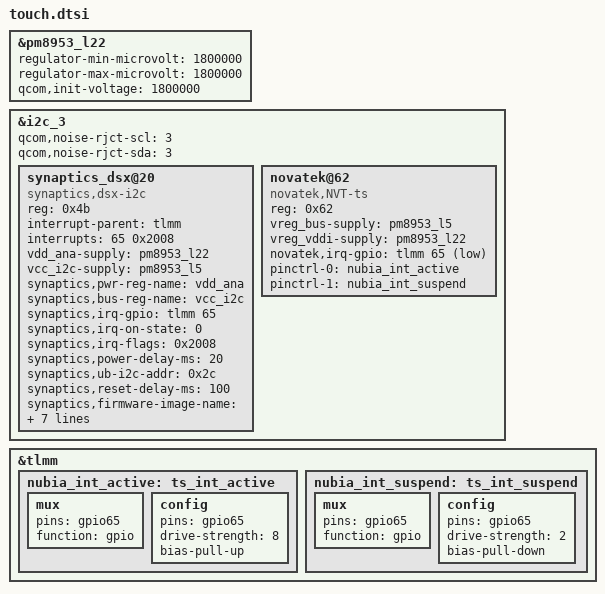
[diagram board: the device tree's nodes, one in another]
/*
 * Copyright (c) 2015-2016, The Linux Foundation. All rights reserved.
 *
 * This program is free software; you can redistribute it and/or modify
 * it under the terms of the GNU General Public License version 2 and
 * only version 2 as published by the Free Software Foundation.
 *
 * This program is distributed in the hope that it will be useful,
 * but WITHOUT ANY WARRANTY; without even the implied warranty of
 * MERCHANTABILITY or FITNESS FOR A PARTICULAR PURPOSE.  See the
 * GNU General Public License for more details.
 */


/*
 * ADD synaptics touch
 */

&pm8953_l22 {
	regulator-min-microvolt = <1800000>;
	regulator-max-microvolt = <1800000>;
	qcom,init-voltage = <1800000>;
};

&i2c_3 {
	status = "okay";

	qcom,noise-rjct-scl = <3>;
	qcom,noise-rjct-sda = <3>;
	synaptics_dsx@20 {
		status = "okay";
		compatible = "synaptics,dsx-i2c";
		reg = <0x4b>;
		interrupt-parent = <&tlmm>;
		interrupts = <65 0x2008>;
		vdd_ana-supply = <&pm8953_l22>;
		vcc_i2c-supply = <&pm8953_l5>;
		synaptics,pwr-reg-name = "vdd_ana";
		synaptics,bus-reg-name = "vcc_i2c";
		synaptics,irq-gpio = <&tlmm 65 0x2008>;
		synaptics,irq-on-state = <0>;
		synaptics,irq-flags = <0x2008>;  //IRQF_ONESHOT | IRQF_TRIGGER_LOW
		synaptics,power-delay-ms = <20>;
		synaptics,ub-i2c-addr = <0x2c>;
		synaptics,reset-delay-ms = <100>;
		synaptics,firmware-image-name = "nubia_tp_jdi_fw.img";
		pinctrl-names = "synaptics_pin_active", "synaptics_pin_suspend";
		pinctrl-0 = <&nubia_int_active>;
		pinctrl-1 = <&nubia_int_suspend>;
		synaptics,full_raw_limit_upper = <
			3191 3164 3092 3075 3136 3067 3068 3095 3017 3011 3035 2990 2994 3042 2991 2958 3033 2950 2967 3025 2970 2975 3021 2981 2984 3035 3004 3010 3079 2984 3048 3158
			2880 2904 2849 2851 2915 2851 2866 2912 2861 2876 2951 2867 2892 2936 2898 2877 2961 2888 2898 2965 2904 2917 2955 2918 2924 2980 2944 2956 3018 2926 2987 3106
			2882 2904 2855 2864 2930 2861 2880 2922 2874 2887 2937 2882 2894 2948 2913 2894 2978 2905 2917 2985 2925 2938 2980 2939 2947 3005 2969 2980 3040 2944 3006 3126
			2893 2910 2861 2871 2939 2871 2892 2938 2883 2903 2956 2893 2909 2978 2925 2909 3004 2919 2935 3009 2941 2959 3015 2956 2974 3035 2988 3004 3079 2956 3049 3158
			2910 2932 2861 2885 2951 2875 2909 2944 2892 2923 2960 2902 2926 2983 2935 2926 3016 2931 2957 3015 2955 2982 3026 2971 2995 3047 3003 3021 3088 2968 3059 3165
			2908 2918 2857 2882 2943 2876 2910 2951 2895 2924 2969 2906 2930 2988 2939 2931 3020 2935 2964 3022 2962 2991 3036 2979 3003 3055 3007 3025 3090 2971 3061 3163
			2899 2911 2852 2878 2941 2875 2910 2951 2895 2926 2970 2908 2933 2990 2941 2935 3023 2938 2966 3025 2964 2995 3039 2983 3009 3060 3011 3031 3095 2973 3066 3163
			2894 2905 2847 2876 2939 2874 2910 2951 2893 2927 2970 2907 2933 2989 2940 2934 3023 2938 2967 3030 2964 2995 3045 2983 3007 3067 3009 3034 3122 2970 3042 3110
			2874 2846 2843 2846 2935 2872 2896 2953 2893 2915 2968 2907 2918 2989 2940 2923 3022 2939 2957 3034 2966 2987 3041 2984 2996 3057 3009 3010 3079 2970 3026 3150
			2880 2868 2922 2853 2876 2946 2890 2897 2979 2889 2911 2993 2936 2932 3007 2953 2974 3023 2958 2973 3063 2978 3014 3069 3007 3022 3083 3002 3009 3033 3016 3057
			2863 2900 2971 2853 2911 2964 2890 2906 2986 2889 2923 2990 2933 2943 3005 2952 2987 3026 2957 2987 3055 2979 3030 3069 3008 3039 3091 3005 3041 3090 3019 3085
			2865 2913 2951 2856 2908 2954 2891 2906 2979 2890 2923 2982 2934 2942 3005 2951 2985 3025 2956 2986 3056 2978 3030 3071 3011 3041 3094 3007 3041 3090 3018 3078
			2872 2917 2956 2859 2909 2955 2893 2905 2978 2889 2921 2979 2932 2940 3002 2948 2981 3023 2954 2982 3053 2977 3027 3068 3008 3039 3092 3006 3040 3090 3018 3073
			2873 2919 2958 2861 2907 2955 2893 2904 2977 2887 2918 2977 2929 2935 2999 2946 2977 3019 2950 2977 3047 2971 3023 3057 3003 3036 3087 3004 3037 3093 3013 3073
			2874 2913 2964 2860 2900 2957 2889 2894 2975 2880 2902 2976 2922 2918 2993 2938 2959 3008 2939 2958 3044 2960 2999 3049 2993 3014 3071 2995 3017 3069 3005 3054
			2872 2893 2941 2856 2887 2936 2883 2878 2955 2871 2890 2957 2913 2906 2971 2927 2943 2980 2926 2941 3018 2945 2980 3025 2977 2996 3051 2982 3003 3056 2993 3041
			2875 2893 2937 2850 2877 2926 2874 2869 2944 2859 2878 2945 2900 2893 2957 2914 2928 2964 2909 2939 3032 2927 2962 3004 2954 2973 3034 2963 2982 3034 2977 3022
			2956 2960 3002 2910 2938 2979 2938 2931 3005 2923 2931 3012 2968 2959 3022 2980 2998 3048 3003 3028 3106 3042 3068 3135 3112 3150 3227 3173 3196 3255 3223 3308

		>;
		synaptics,full_raw_limit_lower = <
			1718 1704 1665 1656 1689 1651 1652 1667 1625 1621 1634 1610 1612 1638 1611 1593 1633 1589 1598 1629 1599 1602 1627 1605 1607 1634 1617 1621 1658 1607 1641 1701
			1551 1564 1534 1535 1570 1535 1543 1568 1541 1549 1589 1544 1557 1581 1560 1549 1595 1555 1560 1596 1564 1571 1591 1571 1574 1604 1585 1592 1625 1576 1608 1673
			1552 1564 1538 1542 1577 1541 1551 1574 1547 1555 1582 1552 1558 1588 1569 1558 1604 1564 1571 1607 1575 1582 1605 1583 1587 1618 1599 1605 1637 1585 1619 1683
			1558 1567 1540 1546 1583 1546 1557 1582 1553 1563 1592 1558 1566 1603 1575 1566 1618 1572 1580 1620 1584 1593 1624 1592 1601 1634 1609 1617 1658 1592 1642 1701
			1567 1579 1541 1554 1589 1548 1566 1585 1557 1574 1594 1562 1576 1606 1580 1575 1624 1578 1592 1623 1591 1606 1629 1600 1613 1641 1617 1627 1663 1598 1647 1704
			1566 1571 1539 1552 1585 1549 1567 1589 1559 1575 1599 1565 1578 1609 1583 1578 1626 1581 1596 1627 1595 1610 1635 1604 1617 1645 1619 1629 1664 1600 1648 1703
			1561 1568 1536 1550 1583 1548 1567 1589 1559 1576 1599 1566 1580 1610 1583 1580 1628 1582 1597 1629 1596 1613 1636 1606 1620 1647 1622 1632 1667 1601 1651 1703
			1558 1564 1533 1549 1582 1547 1567 1589 1558 1576 1599 1565 1579 1609 1583 1580 1628 1582 1597 1632 1596 1613 1640 1606 1619 1651 1620 1634 1681 1599 1638 1675
			1548 1533 1531 1532 1580 1547 1560 1590 1558 1570 1598 1565 1571 1610 1583 1574 1627 1583 1592 1634 1597 1608 1637 1607 1613 1646 1620 1621 1658 1599 1630 1696
			1551 1544 1574 1536 1549 1587 1556 1560 1604 1556 1567 1612 1581 1579 1619 1590 1601 1628 1593 1601 1649 1604 1623 1653 1619 1627 1660 1616 1620 1633 1624 1646
			1542 1562 1600 1536 1568 1596 1556 1565 1608 1555 1574 1610 1579 1585 1618 1589 1609 1629 1592 1608 1645 1604 1632 1653 1620 1637 1665 1618 1637 1664 1626 1661
			1543 1569 1589 1538 1566 1591 1557 1565 1604 1556 1574 1605 1580 1584 1618 1589 1607 1629 1592 1608 1645 1603 1632 1654 1621 1638 1666 1619 1637 1664 1625 1657
			1546 1571 1592 1540 1566 1591 1558 1564 1604 1556 1573 1604 1579 1583 1617 1588 1605 1628 1591 1606 1644 1603 1630 1652 1620 1636 1665 1619 1637 1664 1625 1655
			1547 1572 1593 1541 1565 1591 1558 1564 1603 1554 1571 1603 1577 1580 1615 1586 1603 1626 1589 1603 1641 1600 1628 1646 1617 1635 1662 1617 1635 1665 1622 1655
			1548 1569 1596 1540 1562 1592 1555 1559 1602 1551 1563 1602 1573 1571 1612 1582 1593 1619 1582 1593 1639 1594 1615 1642 1611 1623 1654 1613 1624 1652 1618 1645
			1546 1558 1584 1538 1554 1581 1552 1550 1591 1546 1556 1592 1569 1565 1600 1576 1585 1604 1575 1584 1625 1586 1604 1629 1603 1613 1643 1606 1617 1646 1612 1637
			1548 1558 1582 1535 1549 1576 1547 1545 1585 1540 1550 1586 1562 1558 1592 1569 1577 1596 1567 1583 1632 1576 1595 1617 1591 1601 1634 1595 1606 1634 1603 1627
			1591 1594 1617 1567 1582 1604 1582 1578 1618 1574 1578 1622 1598 1593 1627 1605 1615 1641 1617 1630 1673 1638 1652 1688 1675 1696 1737 1709 1721 1752 1736 1781
		>;
	};

	/* Novatek device tree node */
	novatek@62 {
		compatible = "novatek,NVT-ts";
		reg = <0x62>;
		status = "ok";

		vreg_bus-supply = <&pm8953_l5>;	//pullup
		/*add this to keep vddio enable after suspend*/
		vreg_vddi-supply = <&pm8953_l22>;

		novatek,irq-gpio = <&tlmm 65 0x2001>;
		pinctrl-names = "nvt_pin_active", "nvt_pin_suspend";
		pinctrl-0 = <&nubia_int_active>;
		pinctrl-1 = <&nubia_int_suspend>;
	};
};

&tlmm{
	/*nubia touch screen pinctrl*/
	nubia_int_active: ts_int_active {
		mux {
			pins = "gpio65";
			function = "gpio";
		};
		config {
			pins = "gpio65";
			drive-strength = <8>;
			bias-pull-up;
		};
	};

	nubia_int_suspend: ts_int_suspend {
		mux {
			pins = "gpio65";
			function = "gpio";
		};

		config {
			pins = "gpio65";
			drive-strength = <2>;
			bias-pull-down;
		};
	};
};
